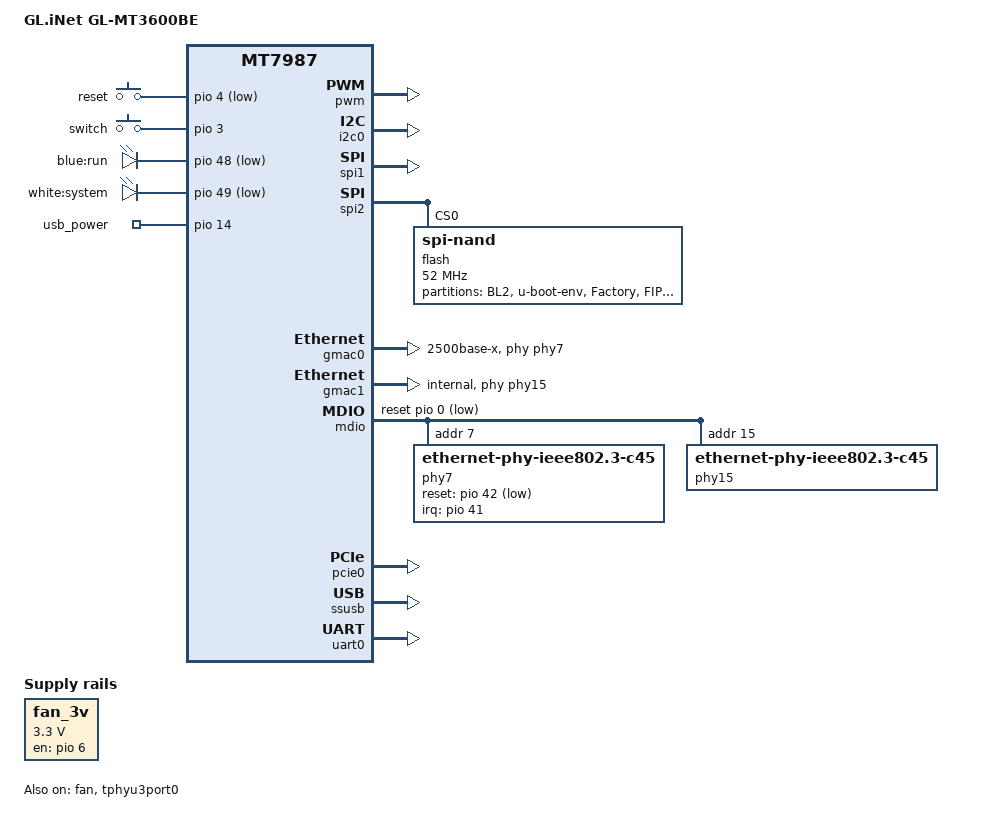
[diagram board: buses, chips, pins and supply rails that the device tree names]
// SPDX-License-Identifier: (GPL-2.0 OR MIT)
/*
 * Author: Developer X <dev@x-wrt.com>
 */

/dts-v1/;
#include "mt7987a.dtsi"
#include <dt-bindings/input/input.h>

/ {
	model = "GL.iNet GL-MT3600BE";
	compatible = "glinet,gl-mt3600be", "mediatek,mt7987a", "mediatek,mt7987";

	aliases {
		label-mac-device = &gmac0;
		led-boot = &led_power;
		led-failsafe = &led_power;
		led-running = &led_power;
		led-upgrade = &led_power;
	};

	chosen {
		bootargs = "console=ttyS0,115200n1 \
			    earlycon=uart8250,mmio32,0x11000000 \
			    pci=pcie_bus_perf";
	};

	gpio-keys {
		compatible = "gpio-keys";

		reset {
			label = "reset";
			linux,code = <KEY_RESTART>;
			gpios = <&pio 4 GPIO_ACTIVE_LOW>;
			debounce-interval = <10>;
		};

		switch {
			label = "switch";
			linux,code = <KEY_SETUP>;
			gpios = <&pio 3 GPIO_ACTIVE_HIGH>;
			debounce-interval = <10>;
		};
	};

	gpio-leds {
		compatible = "gpio-leds";

		led_power: led@0 {
			label = "blue:run";
			gpios = <&pio 48 GPIO_ACTIVE_LOW>;
			default-state = "on";
		};

		led@1 {
			label = "white:system";
			gpios = <&pio 49 GPIO_ACTIVE_LOW>;
		};
	};

	gpio-export {
		compatible = "gpio-export";

		usb_power {
			gpio-export,name = "usb_power";
			gpio-export,output = <1>;
			gpios = <&pio 14 GPIO_ACTIVE_HIGH>;
		};
	};

	fan_3v: regulator-fan-3p3v {
		compatible = "regulator-fixed";
		regulator-name = "fan";
		regulator-min-microvolt = <3300000>;
		regulator-max-microvolt = <3300000>;
		gpio = <&pio 6 GPIO_ACTIVE_HIGH>;
		enable-active-high;
	};
};

&pwm {
	status = "okay";
};

&i2c0 {
	pinctrl-names = "default";
	pinctrl-0 = <&i2c0_pins>;
	status = "okay";
};

&spi1 {
	pinctrl-names = "default";
	pinctrl-0 = <&spic_pins>;
	status = "okay";
};

&spi2 {
	pinctrl-names = "default";
	pinctrl-0 = <&spi2_flash_pins>;
	status = "okay";

	flash@0 {
		compatible = "spi-nand";
		reg = <0>;
		spi-max-frequency = <52000000>;
		spi-rx-bus-width = <4>;
		spi-tx-bus-width = <4>;
		mediatek,nmbm;
		mediatek,bmt-max-ratio = <1>;
		mediatek,bmt-max-reserved-blocks = <64>;

		partitions {
			compatible = "fixed-partitions";
			#address-cells = <1>;
			#size-cells = <1>;

			partition@0 {
				label = "BL2";
				reg = <0x00 0x100000>;
				read-only;
			};

			partition@100000 {
				label = "u-boot-env";
				reg = <0x100000 0x80000>;
			};

			factory: partition@180000 {
				label = "Factory";
				reg = <0x180000 0x400000>;
				read-only;

				nvmem-layout {
					compatible = "fixed-layout";
					#address-cells = <1>;
					#size-cells = <1>;

					macaddr_base: macaddr@4000 {
						reg = <0x4000 0x6>;
						compatible = "mac-base";
						#nvmem-cell-cells = <1>;
					};
				};
			};

			partition@580000 {
				label = "FIP";
				reg = <0x580000 0x200000>;
			};

			partition@780000 {
				label = "log";
				reg = <0x780000 0x40000>;
			};

			partition@7C0000 {
				label = "CFG";
				reg = <0x7c0000 0x40000>;
			};

			partition@800000 {
				label = "ubi";
				reg = <0x800000 0x1d800000>;
			};
		};
	};
};

&fan {
	status = "okay";
	pwms = <&pwm 1 50000 0>;
	fan-supply = <&fan_3v>;
	interrupt-parent = <&pio>;
	interrupts = <5 IRQ_TYPE_EDGE_RISING>;
	cooling-levels = <0x00 0x24 0x24 0x24 0x24 0x24 0x24 0x24 0x24 0x24 0x24 0x24 0x24 0x24 0x24 0x24 0x24 0x24 0x24 0x24 0x24 0x24 0x24 0x24 0x24 0x24 0x24 0x24 0x24 0x24 0x24 0x24 0x24 0x24 0x24 0x24 0x24 0x25 0x26 0x27 0x28 0x29 0x2a 0x2b 0x2c 0x2d 0x2e 0x2f 0x30 0x31 0x32 0x33 0x34 0x35 0x36 0x37 0x38 0x39 0x3a 0x3b 0x3c 0x3d 0x3e 0x3f 0x40 0x41 0x42 0x43 0x44 0x45 0x46 0x47 0x48 0x49 0x4a 0x4b 0x4c 0x4d 0x4e 0x4f 0x50 0x51 0x52 0x53 0x54 0x55 0x56 0x57 0x58 0x59 0x5a 0x5b 0x5c 0x5d 0x5e 0x5f 0x60 0x61 0x62 0x63 0x64 0x65 0x66 0x67 0x68 0x69 0x6a 0x6b 0x6c 0x6d 0x6e 0x6f 0x70 0x71 0x72 0x73 0x74 0x75 0x76 0x77 0x78 0x79 0x7a 0x7b 0x7c 0x7d 0x7e 0x7f 0x80 0x81 0x82 0x83 0x84 0x85 0x86 0x87 0x88 0x89 0x8a 0x8b 0x8c 0x8d 0x8e 0x8f 0x90 0x91 0x92 0x93 0x94 0x95 0x96 0x97 0x98 0x99 0x9a 0x9b 0x9c 0x9d 0x9e 0x9f 0xa0 0xa1 0xa2 0xa3 0xa4 0xa5 0xa6 0xa7 0xa8 0xa9 0xaa 0xab 0xac 0xad 0xae 0xaf 0xb0 0xb1 0xb2 0xb3 0xb4 0xb5 0xb6 0xb7 0xb8 0xb9 0xba 0xbb 0xbc 0xbd 0xbe 0xbf 0xc0 0xc1 0xc2 0xc3 0xc4 0xc5 0xc6 0xc7 0xc8 0xc9 0xca 0xcb 0xcc 0xcd 0xce 0xcf 0xd0 0xd1 0xd2 0xd3 0xd4 0xd5 0xd6 0xd7 0xd8 0xd9 0xda 0xdb 0xdc 0xdd 0xde 0xdf 0xe0 0xe1 0xe2 0xe3 0xe4 0xe5 0xe6 0xe7 0xe8 0xe9 0xea 0xeb 0xec 0xed 0xee 0xef 0xf0 0xf1 0xf2 0xf3 0xf4 0xf5 0xf6 0xf7 0xf8 0xf9 0xfa 0xfb 0xfc 0xfd 0xfe 0xff>;
};

&gmac0 {
	phy-mode = "2500base-x";
	phy-handle = <&phy7>;
	status = "okay";
	nvmem-cells = <&macaddr_base 0>;
	nvmem-cell-names = "mac-address";
};

&gmac1 {
	mac-type = "xgdm";
	phy-mode = "internal";
	phy-handle = <&phy15>;
	status = "okay";
	nvmem-cells = <&macaddr_base 1>;
	nvmem-cell-names = "mac-address";
};

&mdio {
	reset-gpios = <&pio 0 GPIO_ACTIVE_LOW>;
	reset-delay-us = <10000>;

	phy7: phy@7 {
		compatible = "ethernet-phy-ieee802.3-c45";
		reg = <7>;
		reset-assert-us = <100000>;
		reset-deassert-us = <100000>;
		reset-gpios = <&pio 42 GPIO_ACTIVE_LOW>;
		interrupt-controller;
		#interrupt-cells = <1>;
		interrupt-parent = <&pio>;
		interrupts = <41 IRQ_TYPE_LEVEL_LOW>;
	};

	phy15: phy@15 {
		compatible = "ethernet-phy-ieee802.3-c45";
		reg = <15>;
		pinctrl-names = "i2p5gbe-led";
		pinctrl-0 = <&i2p5gbe_led0_pins>;
		phy-mode = "internal";
	};
};

&pcie0 {
	pinctrl-names = "default";
	pinctrl-0 = <&pcie0_pins>;
	status = "okay";
};

&pcie1 {
	pinctrl-names = "default";
	pinctrl-0 = <&pcie1_pins>;
	status = "disabled";
};

&pwm {
	status = "okay";
};

&spi2 {
	pinctrl-names = "default";
	pinctrl-0 = <&spi2_flash_pins>;
	status = "okay";
};

&ssusb {
	status = "okay";
};

&tphyu3port0 {
	status = "okay";
};

&uart0 {
	pinctrl-names = "default";
	pinctrl-0 = <&uart0_pins>;
	status = "okay";
};
